# ESP32-C61 register map
Vendor: ESPRESSIF SYSTEMS (SHANGHAI) CO., LTD.; Series: ESP32 C-Series; File version: 1
CPU: RV32IMAC r0p0, little endian, no MPU, no FPU, 0 interrupt priority bits
Address unit: 32 bits
Registers are 32-bit, read-write, reset 0x0 unless marked. A register's access mark holds for its fields unless they carry their own. Offsets are from the block's base; [hi:lo] are bit positions; {n}, {i} and the like mark numbered series.

## ECC — ECC (ECC Hardware Accelerator)
Base 0x6008B000
0x0C INT_RAW ro — ECC raw interrupt status register
  [0] CALC_DONE_INT_RAW — The raw interrupt status of the ECC_CALC_DONE_INT interrupt.
0x10 INT_ST ro — ECC masked interrupt status register
  [0] CALC_DONE_INT_ST — The masked interrupt status of the ECC_CALC_DONE_INT interrupt.
0x14 INT_ENA — ECC interrupt enable register
  [0] CALC_DONE_INT_ENA — Write 1 to enable the ECC_CALC_DONE_INT interrupt.
0x18 INT_CLR wo — ECC interrupt clear register
  [0] CALC_DONE_INT_CLR — Write 1 to clear the ECC_CALC_DONE_INT interrupt.
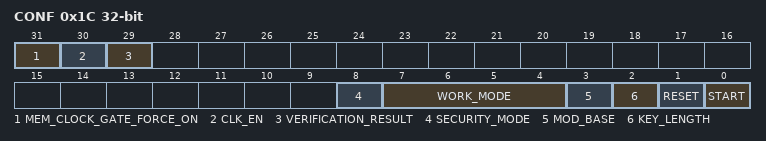
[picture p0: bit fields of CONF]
0x1C CONF access per field — ECC configuration register
  [31] MEM_CLOCK_GATE_FORCE_ON rw — Configures whether to force on ECC memory clock gate. \\ 0: No effect\\ 1: Force on\\
  [30] CLK_EN rw — Configures whether to force on register clock gate. \\ 0: No effect\\ 1: Force on\\
  [29] VERIFICATION_RESULT ro — Represents the verification result of ECC Accelerator, valid only when calculation is done.
  [8] SECURITY_MODE rw — Configures the security mode of ECC Accelerator.\\ 0: no secure function enabled.\\ 1: enable constant-time calculation in all point multiplication modes.\\
  [7:4] WORK_MODE rw — Configures the work mode of ECC Accelerator.\\ 0: Point Multi mode\\ 1: Reserved\\ 2: Point Verif mode\\ 3: Point Verif + Multi mode\\ 4: Jacobian Point Multi mode\\ 5: Reserved\\ 6: Jacobian Point Verif mode\\ 7: Point Verif + Jacobian Point Multi mode\\ 8: Mod Add mode\\ 9. Mod Sub mode\\ 10: Mod Multi mode\\ 11: Mod Div mode\\
  [3] MOD_BASE rw — Configures the mod base of mod operation, only valid in work_mode 8-11. \\ 0: n(order of curve)\\ 1: p(mod base of curve)\\
  [2] KEY_LENGTH rw — Configures the key length mode bit of ECC Accelerator. \\ 0: P-192\\ 1: P-256\\
  [1] RESET wo — Configures whether to reset ECC Accelerator. \\ 0: No effect\\ 1: Reset\\
  [0] START rw — Configures whether to start calculation of ECC Accelerator. This bit will be self-cleared after the calculation is done. \\ 0: No effect\\ 1: Start calculation of ECC Accelerator\\
0xFC DATE reset 0x2401060 — Version control register
  [27:0] DATE — ECC mult version control register
{0x100+4i} K_MEM[{i}] (i=0..7) access not given — The memory that stores k.
{0x120+4i} PX_MEM[{i}] (i=0..7) access not given — The memory that stores Px.
{0x140+4i} PY_MEM[{i}] (i=0..7) access not given — The memory that stores Py.
{0x160+4i} QX_MEM[{i}] (i=0..7) access not given — The memory that stores Qx.
{0x180+4i} QY_MEM[{i}] (i=0..7) access not given — The memory that stores Qy.
{0x1A0+4i} QZ_MEM[{i}] (i=0..7) access not given — The memory that stores Qz.

## HP_APM — HP_APM Peripheral
Base 0x60099000
0x00 REGION_FILTER_EN reset 0x1 — Region filter enable register
  [15:0] REGION_FILTER_EN — Configure bit 0 (0-15) to enable region 0.\\ 0: disable \\ 1: enable \\
{0x4+0xC*i} REGION{i}_ADDR_START (i=0..15) — Region address register
  [31:0] REGION_ADDR_START — Configures start address of region %s.
{0x8+0xC*i} REGION{i}_ADDR_END (i=0..15) reset 0xFFFFFFFF — Region address register
  [31:0] REGION_ADDR_END — Configures end address of region %s.
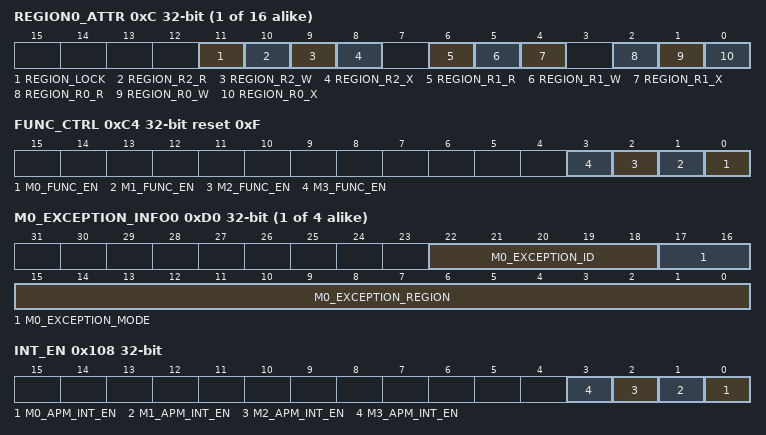
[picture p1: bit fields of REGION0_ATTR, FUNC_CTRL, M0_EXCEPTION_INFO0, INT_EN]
{0xC+0xC*i} REGION{i}_ATTR (i=0..15) — Region access authority attribute register
  [11] REGION_LOCK — Set 1 to lock region0 configuration
  [10] REGION_R2_R — Configures the read authority of REE_MODE 2 in region %s.
  [9] REGION_R2_W — Configures the write authority of REE_MODE 2 in region %s.
  [8] REGION_R2_X — Configures the execution authority of REE_MODE 2 in region %s.
  [6] REGION_R1_R — Configures the read authority of REE_MODE 1 in region %s.
  [5] REGION_R1_W — Configures the write authority of REE_MODE 1 in region %s.
  [4] REGION_R1_X — Configures the execution authority of REE_MODE 1 in region %s.
  [2] REGION_R0_R — Configures the read authority of REE_MODE 0 in region %s.
  [1] REGION_R0_W — Configures the write authority of REE_MODE 0 in region %s.
  [0] REGION_R0_X — Configures the execution authority of REE_MODE 0 in region %s.
0xC4 FUNC_CTRL reset 0xF — APM function control register
  [n] M{n}_FUNC_EN (n=0..3) — PMS M{n} function enable
{0xC8+0x10*i} M{i}_STATUS ro (i=0..3)
  [1:0] M{i}_EXCEPTION_STATUS — Represents exception status.\\ bit0: 1 represents authority_exception \\ bit1: 1 represents space_exception \\
{0xCC+0x10*i} M{i}_STATUS_CLR wo (i=0..3) — M{i} status clear register
  [0] M{i}_EXCEPTION_STATUS_CLR — Configures to clear exception status.
{0xD0+0x10*i} M{i}_EXCEPTION_INFO0 ro (i=0..3)
  [22:18] M{i}_EXCEPTION_ID — Represents exception id information.
  [17:16] M{i}_EXCEPTION_MODE — Represents exception mode.
  [15:0] M{i}_EXCEPTION_REGION — Represents exception region.
{0xD4+0x10*i} M{i}_EXCEPTION_INFO1 ro (i=0..3)
  [31:0] M{i}_EXCEPTION_ADDR — Represents exception addr.
0x108 INT_EN — APM interrupt enable register
  [n] M{n}_APM_INT_EN (n=0..3) — Configures to enable APM M{n} interrupt.\\ 0: disable \\ 1: enable \\
0x7F8 CLOCK_GATE reset 0x1 — Clock gating register
  [0] CLK_EN — Configures whether to keep the clock always on.\\ 0: enable automatic clock gating \\ 1: keep the clock always on \\
0x7FC DATE reset 0x2312200 — Version control register
  [27:0] DATE — Version control register.
